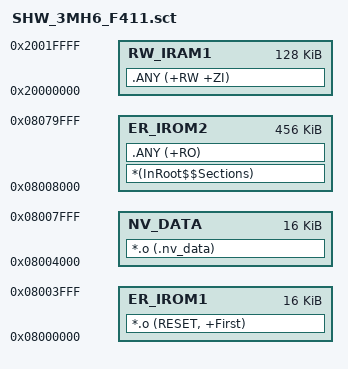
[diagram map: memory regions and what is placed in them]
; *************************************************************
; *** Scatter-Loading Description File generated by uVision ***
; *************************************************************

LR_IROM1 0x08000000 0x00004000  {    ; load region size_region
	ER_IROM1 0x08000000 0x00004000  {  ; load address = execution address
		*.o (RESET, +First)
	}
}

LR_IROM2 0x08004000 0x00004000 {
	NV_DATA 0x08004000 0x00004000 {
		*.o (.nv_data)
	}
}

LR_IROM3 0x08008000 0x00072000 {

	ER_IROM2 0x08008000 0x00072000 {
		*(InRoot$$Sections)
		.ANY (+RO)
	}
	
	
	RW_IRAM1 0x20000000 0x00020000  {  ; RW data
		.ANY (+RW +ZI)
	}
}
